AUTOSAR XML (schema 4.0)
package /Battery_EV_Components
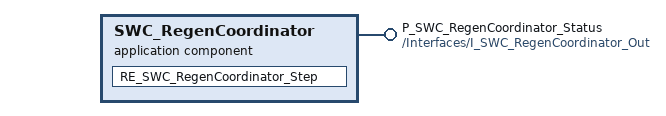
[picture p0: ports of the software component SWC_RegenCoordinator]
  application sw component type SWC_RegenCoordinator  # AUTOSAR Application SWC SWC_RegenCoordinator for Battery EV Safety
    provide port P_SWC_RegenCoordinator_Status: provided-interface=/Interfaces/I_SWC_RegenCoordinator_Out
    behavior SWC_RegenCoordinator_Behavior
      runnable RE_SWC_RegenCoordinator_Step: symbol=SWC_RegenCoordinator_Step
  sender receiver interface I_SWC_RegenCoordinator_Out
    data DE_SWC_RegenCoordinator_Health: type=/AUTOSAR/Platform/uint32
